# HK32F0301M register map
Vendor: HKMicroChip Ltd.; Series: HK32F0301M; File version: 1.0
Arm 32-bit Cortex-M0 Microcontroller based device, CPU clock up to 48 MHz
CPU: CM0 r0p0, little endian, no MPU, no FPU, 3 interrupt priority bits
Registers are 32-bit, read-write, reset 0x0 unless marked. A register's access mark holds for its fields unless they carry their own. Offsets are from the block's base; lines under a group give offsets from that group; [hi:lo] are bit positions; {n}, {i} and the like mark numbered series; 'fields as' and 'values as' point back to an identical list; <NAME> marks a mode.

## Memory map
0x40000000 TIM2 size 0x400 — General-purpose-timers
0x40001000 TIM6 size 0x400 — Basic-timers
0x40002C00 WWDG size 0x400 — Window watchdog
0x40003000 IWDG size 0x400 — Independent watchdog
0x40005400 I2C size 0x400 — Inter-integrated circuit
0x40007000 PWR size 0x400 — Power control
0x40007800 AWU size 0x400 — AWU module
0x40007C00 Beeper size 0x400 — Beeper module
0x40010000 SYSCFG size 0x400 — System configuration controller
0x40010400 EXTI size 0x400 — External interrupt/event controller
0x40012400 ADC size 0x400 — Analog-to-digital converter
0x40012C00 TIM1 size 0x400 — Advanced-timers
0x40013000 SPI size 0x400 — Serial peripheral interface
0x40013800 USART1 size 0x400 — Universal synchronous asynchronous receiver transmitter
0x40015800 DBGMCU size 0x400 — Debug support
0x40017C00 IOMUX size 0x400
0x40021000 RCC size 0x400 — Reset and clock control
0x40022000 Flash size 0x400
0x40023000 CRC size 0x400 — cyclic redundancy check calculation unit
0x48000000 GPIOA size 0x400 — General-purpose I/Os
0x48000400 GPIOB size 0x400
0x48000800 GPIOC size 0x400
0x48000C00 GPIOD size 0x400
0xE000E100 NVIC size 0x33D — Nested Vectored Interrupt Controller

## Interrupts
0 WWDG — Window Watchdog interrupt
2 EXTI11 (RCC) — EXTI Line11 interrupts
3 FLASH (Flash) — Flash global interrupt
4 RCC — RCC global interrupt
5 EXTI0 (RCC) — EXTI Line0 interrupts
6 EXTI1 (RCC) — EXTI Line1 interrupts
7 EXTI2 (RCC) — EXTI Line2 interrupts
8 EXTI3 (RCC) — EXTI Line3 interrupts
9 EXTI4 (RCC) — EXTI Line4 interrupts
10 EXTI5 (RCC) — EXTI Line5 interrupts
11 TIM1_BRK (RCC) — TIM1_BRK interrupts
12 ADC1 (ADC) — ADC1 interrupt
13 TIM1_UP_TRG_COM (TIM1) — TIM1 Update, Trigger and Commutation Interrupt
14 TIM1_CC (TIM1) — TIM1 Capture Compare interrupt
15 TIM2 — TIM2 global interrupt
17 TIM6 — TIM6 global interrupt
21 EXTI6 (RCC) — EXTI Line6 interrupts
22 EXTI7 (RCC) — EXTI and EXTI7 interrupts
23 I2C1 (I2C) — I2C global interrupt
25 SPI1 (SPI) — SPI_global_interrupt
27 USART1 — USART1 global interrupt

## CRC — cyclic redundancy check calculation unit
Base 0x40023000
0x00 DR reset 0xFFFFFFFF — Data register
  [31:0] DR — Data register bits
0x04 IDR — Independent data register
  [7:0] IDR — General-purpose 8-bit data register bits
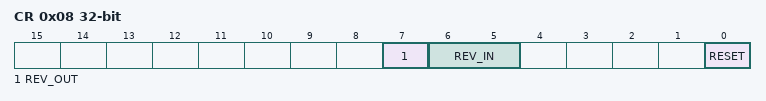
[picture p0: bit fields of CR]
0x08 CR — Control register
  [7] REV_OUT — Reverse output data
  [6:5] REV_IN — Reverse input data
  [0] RESET — reset bit
0x10 INIT reset 0xFFFFFFFF — Initial CRC value
  [31:0] INIT — Programmable initial CRC value

## GPIOA — General-purpose I/Os
Base 0x48000000
Same registers: GPIOB 0x48000400, GPIOC 0x48000800, GPIOD 0x48000C00
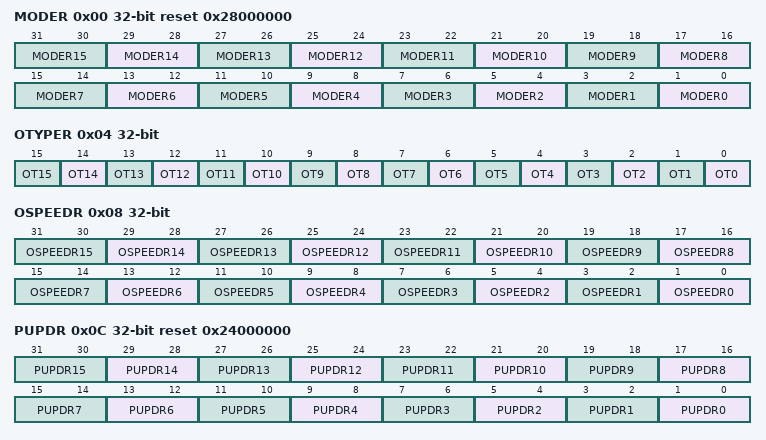
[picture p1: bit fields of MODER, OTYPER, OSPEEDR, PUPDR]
0x00 MODER reset 0x28000000 — GPIO port mode register
  [2n+1:2n] MODER{n} (n=0..15) — Port x configuration bits (y = 0..15)
0x04 OTYPER — GPIO port output type register
  [n] OT{n} (n=0..15) — Port x configuration bits (y = 0..15)
0x08 OSPEEDR — GPIO port output speed register
  [2n+1:2n] OSPEEDR{n} (n=0..15) — Port x configuration bits (y = 0..15)
0x0C PUPDR reset 0x24000000 — GPIO port pull-up/pull-down register
  [2n+1:2n] PUPDR{n} (n=0..15) — Port x configuration bits (y = 0..15)
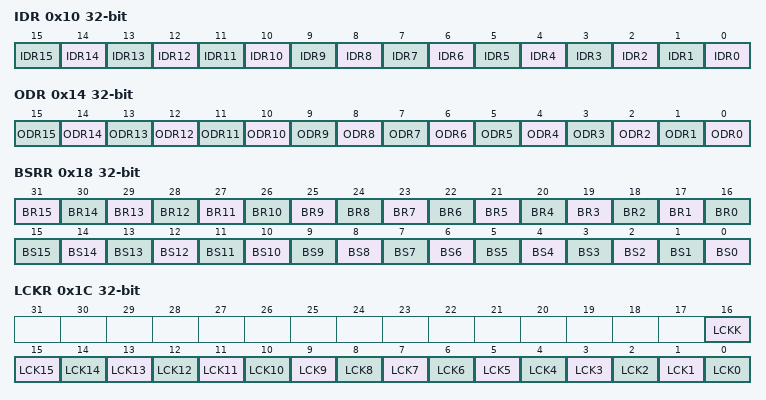
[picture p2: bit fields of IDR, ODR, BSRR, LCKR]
0x10 IDR ro — GPIO port input data register
  [n] IDR{n} (n=0..15) — Port input data (y = 0..15)
0x14 ODR — GPIO port output data register
  [n] ODR{n} (n=0..15) — Port output data (y = 0..15)
0x18 BSRR wo — GPIO port bit set/reset register
  [n+16] BR{n} (n=1..15) — Port x reset bit y (y = 0..15)
  [16] BR0 — Port x set bit y (y= 0..15)
  [n] BS{n} (n=0..15) — Port x set bit y (y= 0..15)
0x1C LCKR — GPIO port configuration lock register
  [16] LCKK — Port x lock bit y (y= 0..15)
  [n] LCK{n} (n=0..15) — Port x lock bit y (y= 0..15)
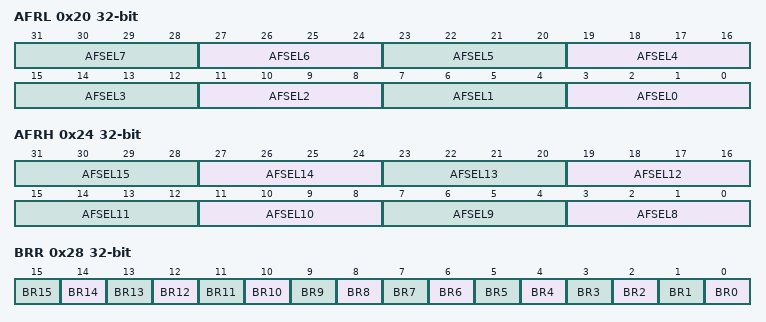
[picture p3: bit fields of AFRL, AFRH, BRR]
0x20 AFRL — GPIO alternate function low register
  [4n+3:4n] AFSEL{n} (n=0..7) — Alternate function selection for port x bit y (y = 0..7)
0x24 AFRH — GPIO alternate function high register
  [4n-29:4n-32] AFSEL{n} (n=8..15) — Alternate function selection for port x bit y (y = 8..15)
0x28 BRR wo — Port bit reset register
  [n] BR{n} (n=0..15) — Port x Reset bit y
0x30 IOSR
  [15:0] IOSENX

## Licence text in the file
HKMicroChip Limited (HKMicroChip) is supplying this software for use with Cortex-M0!
